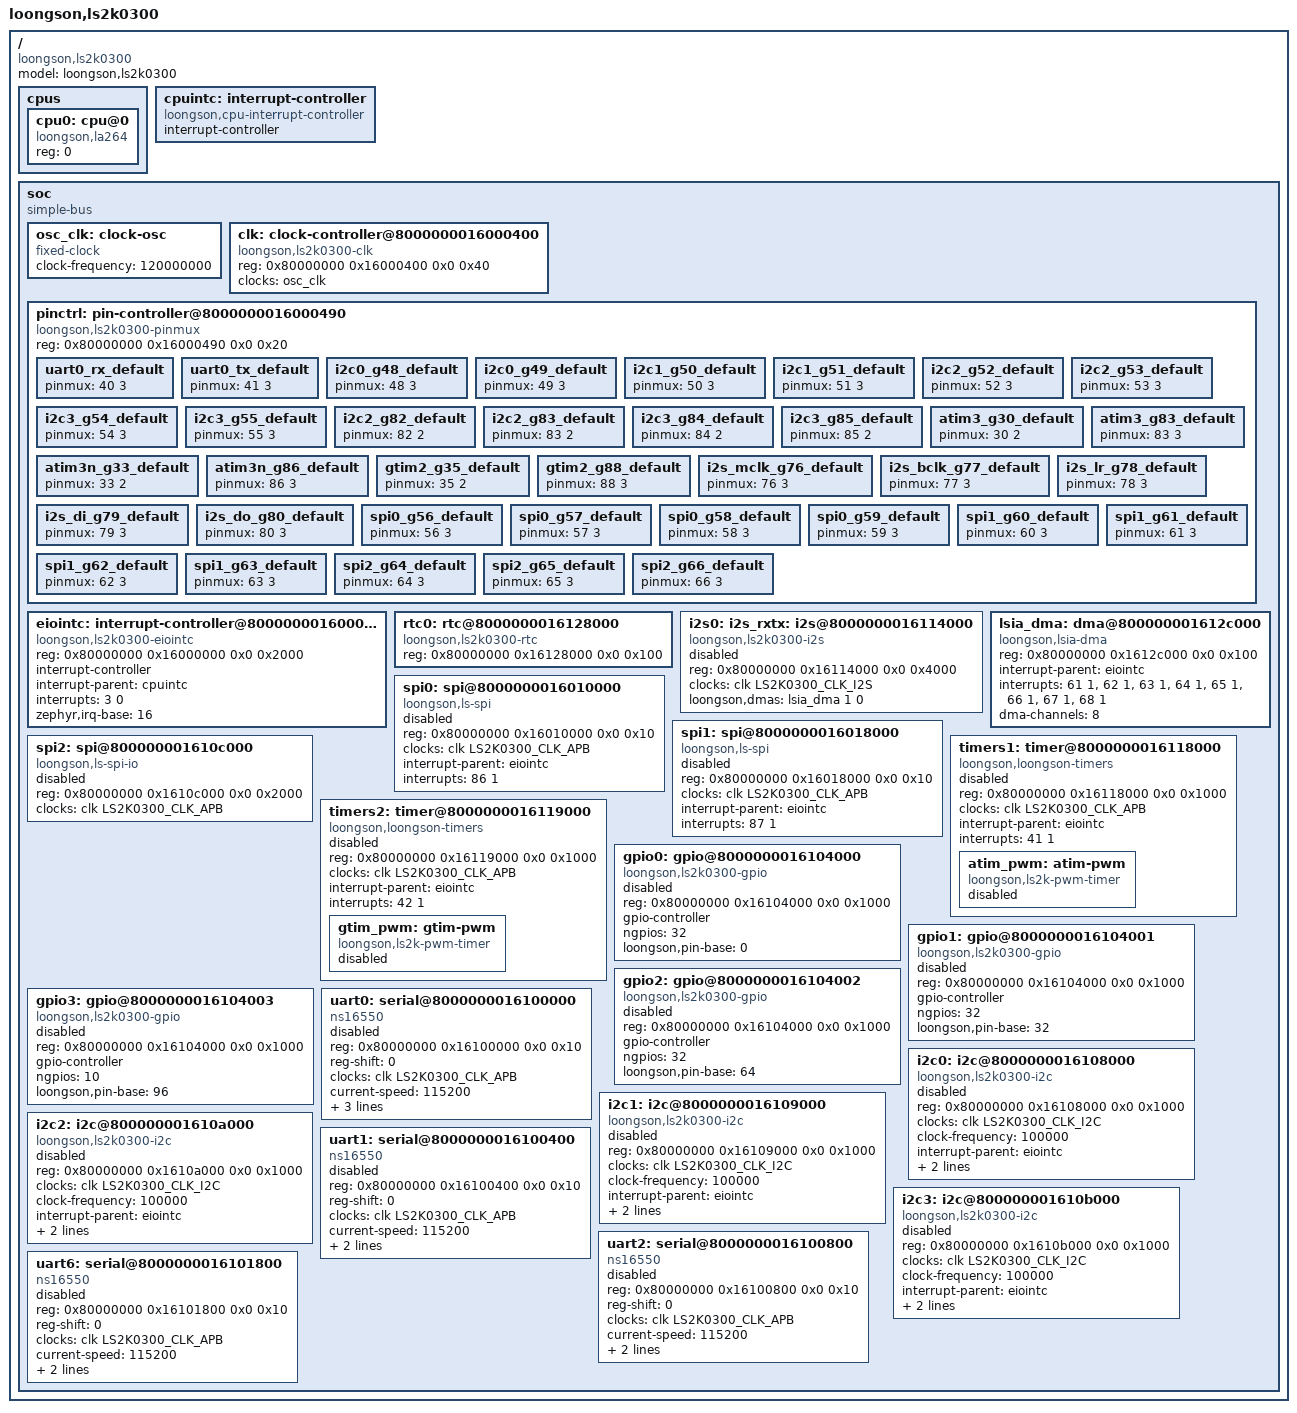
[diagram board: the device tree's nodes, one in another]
/*
 * SPDX-License-Identifier: Apache-2.0
 *
 * Loongson 2K0300 (LS2K0300, "ls2k300" family) - single LA264 core.
 *
 * Physical memory map:
 *
 *   0x9000_0000_0000_0000  DDR (size is board specific)
 *   0x1600_0000            SoC peripherals (LIO / APB)
 *   0x1640_0000            legacy ISA window
 *
 * Interrupts are numbered in a flat, SoC wide space:
 *
 *   0..15    CPU interrupt lines (ESTAT.IS[15:0], enabled through ECFG.LIE)
 *   16..143  EIOINTC vectors 0..127
 *
 * Peripheral nodes therefore carry the *flat* number in their "interrupts"
 * entry (e.g. <16 1> is vector 0 of the EIOINTC with priority 1).
 *
 * The EIOINTC is the interrupt controller of this port: the SoC wires every
 * peripheral interrupt to it, each source with a vector of its own. Its
 * predecessor, the legacy LIOINTC, is not modelled - it aggregates several
 * sources per line (uart2..uart5 share one, for example), which a static ISR
 * table can only serve one of - and its driver, binding and nodes were removed
 * once the EIOINTC took over. Its hardware facts are kept in the port notes
 * (`.vscode/skills/ls2k0300-port/references/hardware-registers.md`) for a
 * future 2K SoC that has no extended controller.
 */

/dts-v1/;

#include <zephyr/dt-bindings/clock/loongson,ls2k0300-clk.h>

/ {
	#address-cells = <2>;
	#size-cells = <2>;
	model = "loongson,ls2k0300";
	compatible = "loongson,ls2k0300";

	cpus {
		#address-cells = <1>;
		#size-cells = <0>;

		cpu0: cpu@0 {
			device_type = "cpu";
			compatible = "loongson,la264";
			reg = <0>;
		};
	};

	cpuintc: interrupt-controller {
		compatible = "loongson,cpu-interrupt-controller";
		interrupt-controller;
		#interrupt-cells = <2>;
	};

	soc {
		#address-cells = <2>;
		#size-cells = <2>;
		compatible = "simple-bus";
		ranges;

		/*
		 * The 120 MHz reference oscillator and the clock controller.
		 *
		 * The controller is driven read only: u-boot locks the PLLs before
		 * it hands over, so a consumer asks for the resulting rate instead
		 * of carrying a hard coded frequency in its node:
		 *
		 *     clocks = <&clk LS2K0300_CLK_APB>;
		 *
		 * That matters most for the console UART, whose baud rate divisor
		 * is CLKin / (16 * baud) and which therefore needs the real APB
		 * clock (200 MHz on this board), not a guess.
		 */
		osc_clk: clock-osc {
			compatible = "fixed-clock";
			#clock-cells = <0>;
			clock-frequency = <120000000>;
		};

		clk: clock-controller@8000000016000400 {
			compatible = "loongson,ls2k0300-clk";
			reg = <0x80000000 0x16000400 0x0 0x40>;
			clocks = <&osc_clk>;
			clock-names = "ref_clk";
			#clock-cells = <1>;
			status = "okay";
		};

		/*
		 * Pin mux: the GPIO_CFG registers at 0x1600_0490, two bits per
		 * GPIO (16 pins per register). A state lists (pin, function)
		 * pairs, see dts/bindings/pinctrl/loongson,ls2k0300-pinmux.yaml.
		 */
		pinctrl: pin-controller@8000000016000490 {
			compatible = "loongson,ls2k0300-pinmux";
			reg = <0x80000000 0x16000490 0x0 0x20>;
			status = "okay";

			/*
			 * Console pins: GPIO40 = uart0_rx, GPIO41 = uart0_tx,
			 * both on their primary function. This is the same setting
			 * the vendor device tree writes as
			 * "pinctrl-single,bits = <0x8 0x000f0000 0x000f0000>".
			 *
			 * Needed because u-boot only configures what it drives:
			 * measured on this board uart0_rx was still left in the
			 * GPIO setting, so the console transmitted but never
			 * received and the shell could not be typed into.
			 */
			uart0_rx_default: uart0_rx_default {
				pinmux = <40 3>;
			};

			uart0_tx_default: uart0_tx_default {
				pinmux = <41 3>;
			};

			/*
			 * I2C pins, all on their primary function, the same
			 * setting the vendor device tree writes for GPIO48..55
			 * in the pin mux word at offset 0xc (GPIO_CFG3):
			 *
			 *   i2c0_pins: pinctrl-single,bits = <0xc 0x0000000f 0x0000000f>;
			 *   i2c1_pins: pinctrl-single,bits = <0xc 0x000000f0 0x000000f0>;
			 *   i2c2_pins: pinctrl-single,bits = <0xc 0x00000f00 0x00000f00>;
			 *   i2c3_pins: pinctrl-single,bits = <0xc 0x0000f000 0x0000f000>;
			 */
			i2c0_g48_default: i2c0_g48_default {
				pinmux = <48 3>;
			};

			i2c0_g49_default: i2c0_g49_default {
				pinmux = <49 3>;
			};

			i2c1_g50_default: i2c1_g50_default {
				pinmux = <50 3>;
			};

			i2c1_g51_default: i2c1_g51_default {
				pinmux = <51 3>;
			};

			i2c2_g52_default: i2c2_g52_default {
				pinmux = <52 3>;
			};

			i2c2_g53_default: i2c2_g53_default {
				pinmux = <53 3>;
			};

			i2c3_g54_default: i2c3_g54_default {
				pinmux = <54 3>;
			};

			i2c3_g55_default: i2c3_g55_default {
				pinmux = <55 3>;
			};

			/*
			 * Mainline also defines an alternative pad group for i2c2
			 * and i2c3, on function 2 instead of 3:
			 *
			 *   i2c2_G82_G83_pins: pinctrl-single,bits = <0x14 0x000000a0 0x000000f0>;
			 *   i2c3_G84_G85_pins: pinctrl-single,bits = <0x14 0x00000a00 0x00000f00>;
			 *
			 * i.e. both fields 0b10 in the pin mux word at offset 0x14
			 * (GPIO80..95). A board picks one group per bus by
			 * referencing its two states in the controller's pinctrl-0;
			 * the controllers above default to the G52..G55 group.
			 */
			i2c2_g82_default: i2c2_g82_default {
				pinmux = <82 2>;
			};

			i2c2_g83_default: i2c2_g83_default {
				pinmux = <83 2>;
			};

			i2c3_g84_default: i2c3_g84_default {
				pinmux = <84 2>;
			};

			i2c3_g85_default: i2c3_g85_default {
				pinmux = <85 2>;
			};

			/*
			 * ATIM/GTIM channel pins, taken from the vendor device
			 * tree's pin mux table (each entry's
			 * "pinctrl-single,bits" decoded to the port's
			 * (pin, function) form). Channel 3 is the one Linux muxes
			 * for the LCD backlight on the 99pi board:
			 *
			 *   ATIM1 G28 f2 / G81 f3    ATIM1N G31 f2 / G84 f3
			 *   ATIM2 G29 f2 / G82 f3    ATIM2N G32 f2 / G85 f3
			 *   ATIM3 G30 f2 / G83 f3    ATIM3N G33 f2 / G86 f3
			 *   ATIM4 G76 f1 / G101 f1
			 *   GTIM1 G34 f2 / G87 f3    GTIM2 G35 f2 / G88 f3
			 *   GTIM3 G36 f2 / G89 f3    GTIM4 G77 f1 / G102 f1
			 *
			 * A board picks one pin per channel. Note that G82..G85
			 * also carry the alternative i2c2/i2c3 groups above, so a
			 * board that uses those buses must take its PWM channels
			 * elsewhere (G30 for channel 3, G28/G29 for 1/2, ...).
			 */
			atim3_g30_default: atim3_g30_default {
				pinmux = <30 2>;
			};

			atim3_g83_default: atim3_g83_default {
				pinmux = <83 3>;
			};

			/*
			 * The complementary outputs exist on the ATIM only
			 * (ATIM1N..ATIM3N, i.e. CH1N..CH3N); the driver enables
			 * them together with their channel, so referencing one of
			 * these states in the block's pinctrl-0 is all it takes
			 * to bring the pin out.
			 */
			atim3n_g33_default: atim3n_g33_default {
				pinmux = <33 2>;
			};

			atim3n_g86_default: atim3n_g86_default {
				pinmux = <86 3>;
			};

			/*
			 * GTIM channel 2 (the "TIM2_CH2" of the vendor tables):
			 * GPIO35 carries it on the m0 mux, GPIO88 on m1 - the pin
			 * Linux switches for the 99pi's second PWM group. Add the
			 * pins of the other channels from the table above the same
			 * way (three lines per pin).
			 */
			gtim2_g35_default: gtim2_g35_default {
				pinmux = <35 2>;
			};

			gtim2_g88_default: gtim2_g88_default {
				pinmux = <88 3>;
			};

			/*
			 * I2S pins, all on their I2S function. The mapping is the
			 * one of the manual's pin table and of the vendor device
			 * tree's "i2s_pins" group:
			 *
			 *   GPIO76 = i2s_mclk     GPIO79 = i2s_datai
			 *   GPIO77 = i2s_bclk     GPIO80 = i2s_datao
			 *   GPIO78 = i2s_lr
			 *
			 * GPIO76 also carries ATIM4 (function 1), GPIO77 GTIM4
			 * (function 1), so a board picks one of the two functions
			 * per pin by referencing the matching state.
			 */
			i2s_mclk_g76_default: i2s_mclk_g76_default {
				pinmux = <76 3>;
			};

			i2s_bclk_g77_default: i2s_bclk_g77_default {
				pinmux = <77 3>;
			};

			i2s_lr_g78_default: i2s_lr_g78_default {
				pinmux = <78 3>;
			};

			i2s_di_g79_default: i2s_di_g79_default {
				pinmux = <79 3>;
			};

			i2s_do_g80_default: i2s_do_g80_default {
				pinmux = <80 3>;
			};

			/*
			 * SPI0/SPI1 pins, all on their main function - the
			 * vendor device tree's "spi0_pins"/"spi1_pins" groups
			 * decoded to the port's (pin, function) form:
			 *
			 *   SPI0 G56 GCLK / G57 MISO / G58 MOSI / G59 CS
			 *   SPI1 G60 GCLK / G61 MISO / G62 MOSI / G63 CS
			 */
			spi0_g56_default: spi0_g56_default {
				pinmux = <56 3>;
			};

			spi0_g57_default: spi0_g57_default {
				pinmux = <57 3>;
			};

			spi0_g58_default: spi0_g58_default {
				pinmux = <58 3>;
			};

			spi0_g59_default: spi0_g59_default {
				pinmux = <59 3>;
			};

			spi1_g60_default: spi1_g60_default {
				pinmux = <60 3>;
			};

			spi1_g61_default: spi1_g61_default {
				pinmux = <61 3>;
			};

			spi1_g62_default: spi1_g62_default {
				pinmux = <62 3>;
			};

			spi1_g63_default: spi1_g63_default {
				pinmux = <63 3>;
			};

			/*
			 * SPI2 pins on their main function - the vendor device
			 * tree's "spi2_pins" group decoded (G64 = clock,
			 * G65 = miso, G66 = mosi). GPIO67, the fourth pin of
			 * the group, stays a GPIO: the ls-spi-io block has no
			 * chip select register, so its CS line is driven as a
			 * plain GPIO (the controller's "cs-gpios").
			 */
			spi2_g64_default: spi2_g64_default {
				pinmux = <64 3>;
			};

			spi2_g65_default: spi2_g65_default {
				pinmux = <65 3>;
			};

			spi2_g66_default: spi2_g66_default {
				pinmux = <66 3>;
			};
		};

		/*
		 * EIOINTC ("EXTIOI"): 128 extended interrupt vectors, each one
		 * separately maskable and routable, all of them cascaded onto CPU
		 * line 3 (INT1 - the vendor device tree cascades it there as
		 * well). The vector assignment is table 3-48 of the 2K0300 user
		 * manual:
		 *
		 *   0..9     UART0..UART9       70, 71    SPI0, SPI1
		 *   10..13   I2C0..I2C3         75, 76    GMAC0, GMAC1
		 *   14, 15   SPI2, SPI3         78        THSENS
		 *   16..23   CAN0..CAN3 core and buffer each
		 *   25..27   ATIMER, GTIMER, BTIMER
		 *   28..31   PWM0..PWM3
		 *   45..52   APB-DMA0..APB-DMA7
		 *   62..64   RTC-INT0..RTC-INT2
		 *   79..105  GPIO0..GPIO105, four pins per vector
		 *
		 * "reg" is the SoC system register window: the controller's
		 * register file sits at offset 0x1600 (enable), 0x1640
		 * (polarity), 0x1700 (device status), 0x1800 (per core status and
		 * clear) and 0x14c0 (vector routing), and the master enable is bit
		 * 19 of the chip configuration register at offset 0x100.
		 */
		eiointc: interrupt-controller@8000000016000000 {
			compatible = "loongson,ls2k0300-eiointc";
			reg = <0x80000000 0x16000000 0x0 0x2000>;
			interrupt-controller;
			#interrupt-cells = <2>;
			interrupt-parent = <&cpuintc>;
			interrupts = <3 0>;
			zephyr,irq-base = <16>;
		};

		/*
		 * RTC: battery backed wall clock. The block's TOY counter counts
		 * year/month/day/hour/minute/second (plus tenths) off the
		 * 32.768 kHz crystal and is the time the driver reads and
		 * writes; the register map is chapter 25 of the user manual.
		 *
		 * Its TOY match alarm does not work on this SoC (mainline Linux
		 * carries the variant under LOONGSON_RTC_ALARM_WORKAROUND), so
		 * the node carries no interrupt even though the interrupt tables
		 * list RTC-INT0..2 / RTC-TICK / TOY-TICK.
		 *
		 * Always present and needing no pins, so it is enabled here
		 * rather than per board.
		 */
		rtc0: rtc@8000000016128000 {
			compatible = "loongson,ls2k0300-rtc";
			reg = <0x80000000 0x16128000 0x0 0x100>;
			status = "okay";
		};

		/*
		 * I2S controller ("IIS", user manual chapter 11): one stereo
		 * interface with an 8 byte FIFO per direction, an integer bit
		 * clock divider and a fractional divider for the codec system
		 * clock (MCLK) that the bit clock is derived from.
		 *
		 * Its interrupt is EIOINTC vector 24 (flat IRQ 40); the block's
		 * interrupt sources stay unused - they report FIFO
		 * overflow/underflow, which cannot pace a stream - so the node
		 * carries no interrupt property. The data path is paced by the
		 * DMA controller below instead.
		 *
		 * Kept disabled here: the five interface pins (GPIO76 MCLK,
		 * GPIO77 BCLK, GPIO78 LR, GPIO79 data in, GPIO80 data out) are
		 * board wiring, and so is the question whether anything drives
		 * the codec system clock.
		 */
		/* The second label is what samples/drivers/i2s/echo looks for */
		i2s0: i2s_rxtx: i2s@8000000016114000 {
			compatible = "loongson,ls2k0300-i2s";
			reg = <0x80000000 0x16114000 0x0 0x4000>;
			#address-cells = <1>;
			#size-cells = <0>;
			/*
			 * The clock both dividers count against (the bit clock
			 * ratio in IISConfig0, the system clock ratio in
			 * IISConfig1). The manual calls it the "bus clock" and
			 * the vendor device tree carries clock-frequency =
			 * <100000000> for this node; on this board the clock
			 * controller reports exactly that - 100 MHz - for
			 * LS2K0300_CLK_I2S (the NODE PLL branch of the
			 * controller), while LS2K0300_CLK_APB, the bus clock of
			 * the UART/I2C/... peripherals, is 200 MHz. The vendor's
			 * own config1 math divides that 100 MHz down to its
			 * 128 fs system clock, which is the same number, so this
			 * property points at the I2S clock.
			 *
			 * If a board turns out to divide another clock, pointing
			 * this property at it is the single change needed - the
			 * driver just reads "clocks".
			 */
			clocks = <&clk LS2K0300_CLK_I2S>;
			/*
			 * The DMA controller moves the data: its transmit request
			 * is wired to channel 1 and its receive request to channel
			 * 0, which is the mapping the vendor device tree uses
			 * ("dmas = <&dma 0 0xaf>, <&dma 1 0xbf>"). There is no
			 * request select register, so these two numbers are all
			 * there is to get right.
			 */
			loongson,dmas = <&lsia_dma 1 0>;
			status = "disabled";
		};

		/*
		 * LSIA DMA controller, "dma@1612c000" in the vendor tree
		 * (compatible "loongson,lsia-dma"): eight channels, four
		 * registers each 0x14 apart - CCR at 0x08, CNDTR at 0x0c, CPAR at
		 * 0x10, CMAR at 0x14 - plus two status registers at 0x00/0x04
		 * holding a four bit nibble per channel (transfer complete in
		 * bit 1, half transfer in bit 2). The vendor kernel drives it
		 * through drivers/dma/lsia_dma.c, this port through
		 * drivers/dma/dma_loongson_lsia.c.
		 *
		 * The data requests are wired to fixed channels - the I2S
		 * transmit on channel 1 and its receive on channel 0 - and the
		 * controller has no request select register, so a consumer
		 * names its channel and nothing else (the "loongson,dmas"
		 * property of the I2S node carries both of its channels for
		 * that driver).
		 */
		lsia_dma: dma@800000001612c000 {
			compatible = "loongson,lsia-dma";
			reg = <0x80000000 0x1612c000 0x0 0x100>;
			/*
			 * One interrupt line per channel: APB-DMA0..7 on vectors
			 * 45..52 of table 3-48 - 61..68 in the flat, SoC wide
			 * numbering this port carries in "interrupts". Confirmed
			 * on hardware: with the channels running, the EIOINTC's
			 * raw, enable-independent status latches exactly vector
			 * 46 (channel 1) while channel 0's expected bit stays
			 * clear. (The vendor tree lists the same lines as
			 * liointc0 inputs 23..30 - those legacy numbers are not
			 * this controller's vectors; a translation read off
			 * liointc input arithmetic put the channels on 23..30
			 * once and the board silently disagreed.)
			 */
			interrupt-parent = <&eiointc>;
			interrupts = <61 1>, <62 1>, <63 1>, <64 1>,
				     <65 1>, <66 1>, <67 1>, <68 1>;
			dma-channels = <8>;
			#dma-cells = <2>;
			/* The namespaced form, for the "loongson,dmas" property */
			#loongson,dma-cells = <2>;
			status = "okay";
		};

		/*
		 * SPI0/SPI1, "spi@0x16010000"/"spi@0x16018000" of the vendor
		 * device tree (compatible "loongson,ls-spi", user manual
		 * chapter 9): a simple polled SPI master with a one byte FIFO
		 * port, four hardware chip selects and the APB/DEVS clock
		 * (200 MHz on this board) as its divider input, so SCLK runs
		 * from 100 MHz down to about 49 kHz.
		 *
		 * The same block also drives a memory-mapped flash window
		 * (SPI0 boot at 0x1c000000, MEM at 0x10000000) that u-boot uses
		 * for XIP; the driver leaves SFC_PARAM.memory_en cleared and
		 * drives the bus purely through the IO registers. The two
		 * "loongson,ls-spi-io" blocks (SPI2 @0x1610c000, SPI3
		 * @0x1610e000) are a different register file (CR1..CR3, CFG1..3)
		 * and are not modelled here.
		 */
		spi0: spi@8000000016010000 {
			compatible = "loongson,ls-spi";
			reg = <0x80000000 0x16010000 0x0 0x10>;
			clocks = <&clk LS2K0300_CLK_APB>;
			clock-names = "apb";
			#address-cells = <1>;
			#size-cells = <0>;
			interrupt-parent = <&eiointc>;
			interrupts = <86 1>; /* vector 70, table 3-48 */
			status = "disabled";
		};

		spi1: spi@8000000016018000 {
			compatible = "loongson,ls-spi";
			reg = <0x80000000 0x16018000 0x0 0x10>;
			clocks = <&clk LS2K0300_CLK_APB>;
			clock-names = "apb";
			#address-cells = <1>;
			#size-cells = <0>;
			interrupt-parent = <&eiointc>;
			interrupts = <87 1>; /* vector 71, table 3-48 */
			status = "disabled";
		};

		/*
		 * SPI2, "spi@0x1610c000" of the vendor device tree
		 * (compatible "loongson,ls-spi-io"): the second register file
		 * (user manual chapter 10) - 32 bit registers, one byte per
		 * CSTART transfer, and no hardware chip selects (a board
		 * drives its CS lines as plain GPIOs through "cs-gpios").
		 * SPI3 (0x1610e000) is the same design and is left out until a
		 * board needs it.
		 */
		spi2: spi@800000001610c000 {
			compatible = "loongson,ls-spi-io";
			reg = <0x80000000 0x1610c000 0x0 0x2000>;
			clocks = <&clk LS2K0300_CLK_APB>;
			clock-names = "apb";
			#address-cells = <1>;
			#size-cells = <0>;
			status = "disabled";
		};

		/*
		 * SoC timer blocks, ported from the vendor Linux device tree
		 * (arch/loongarch/boot/dts/loongson-2k0300.dtsi, "timers1" and
		 * "timers2"): STM32 style general purpose timers on the APB bus
		 * (user manual chapters 18/19), four channels each, input capture
		 * and output compare/PWM. Interrupt mapping and the (unused)
		 * BTIM block are described in the binding.
		 *
		 * Both blocks stay disabled like in Linux - the channel pins are
		 * board wiring - and each one carries the PWM child that Linux
		 * hangs off it, which is what the PWM driver binds to
		 * (drivers/pwm/pwm_loongson_ls_timer.c). The two blocks are
		 * independent, so a board that enables both gets two PWM
		 * frequencies at the same time.
		 *
		 * Linux names both children "pwm"; here they are called
		 * "atim-pwm" and "gtim-pwm" instead, because a Zephyr device is
		 * addressed by its node name and two devices with the same name
		 * would be indistinguishable (the node labels atim_pwm/gtim_pwm
		 * work as well).
		 *
		 * Left out of the Linux node: "dmas"/"dma-names", which this port
		 * has no DMA controller node for - only the capture path needs
		 * them, and capture is not implemented.
		 */
		timers1: timer@8000000016118000 {
			compatible = "loongson,loongson-timers";
			reg = <0x80000000 0x16118000 0x0 0x1000>;
			clocks = <&clk LS2K0300_CLK_APB>;
			clock-names = "int";
			interrupt-parent = <&eiointc>;
			interrupts = <41 1>;
			status = "disabled";

			atim_pwm: atim-pwm {
				compatible = "loongson,ls2k-pwm-timer";
				#pwm-cells = <3>;
				status = "disabled";
			};
		};

		timers2: timer@8000000016119000 {
			compatible = "loongson,loongson-timers";
			reg = <0x80000000 0x16119000 0x0 0x1000>;
			clocks = <&clk LS2K0300_CLK_APB>;
			clock-names = "int";

			interrupt-parent = <&eiointc>;
			interrupts = <42 1>;
			status = "disabled";

			gtim_pwm: gtim-pwm {
				compatible = "loongson,ls2k-pwm-timer";
				#pwm-cells = <3>;
				status = "disabled";
			};
		};

		/*
		 * GPIO controller: 106 byte-controlled pins, split into banks
		 * of at most 32 pins so that Zephyr pin numbers stay within
		 * the 32 bit port mask of the GPIO API. The interrupt part of
		 * the block is not modelled yet.
		 *
		 * Bank N covers IP pins (N * 32) .. (N * 32 + ngpios - 1),
		 * e.g. the backlight/user LED line GPIO43 is <&gpio1 11>.
		 *
		 * All banks share the one 4 KiB register block, so they carry the
		 * same reg value and the unit addresses in the node names exist
		 * only to keep the names unique. dtc flags that as a
		 * simple_bus_reg warning; the alternative would be to encode an
		 * address per bank that the hardware does not have.
		 */
		gpio0: gpio@8000000016104000 {
			compatible = "loongson,ls2k0300-gpio";
			reg = <0x80000000 0x16104000 0x0 0x1000>;
			gpio-controller;
			#gpio-cells = <2>;
			ngpios = <32>;
			loongson,pin-base = <0>;
			status = "disabled";
		};

		gpio1: gpio@8000000016104001 {
			compatible = "loongson,ls2k0300-gpio";
			reg = <0x80000000 0x16104000 0x0 0x1000>;
			gpio-controller;
			#gpio-cells = <2>;
			ngpios = <32>;
			loongson,pin-base = <32>;
			status = "disabled";
		};

		gpio2: gpio@8000000016104002 {
			compatible = "loongson,ls2k0300-gpio";
			reg = <0x80000000 0x16104000 0x0 0x1000>;
			gpio-controller;
			#gpio-cells = <2>;
			ngpios = <32>;
			loongson,pin-base = <64>;
			status = "disabled";
		};

		gpio3: gpio@8000000016104003 {
			compatible = "loongson,ls2k0300-gpio";
			reg = <0x80000000 0x16104000 0x0 0x1000>;
			gpio-controller;
			#gpio-cells = <2>;
			ngpios = <10>;
			loongson,pin-base = <96>;
			status = "disabled";
		};

		/*
		 * MMIO is reached through the uncached direct map window
		 * (0x8000_0000_0000_0000 | physical address), which reset.S
		 * programs as DMW0. The plain physical address 0x1610_0000 is
		 * not inside any direct map window, so using it would need a TLB
		 * entry the kernel does not own and would fault.
		 */
		uart0: serial@8000000016100000 {
			compatible = "ns16550";
			reg = <0x80000000 0x16100000 0x0 0x10>;
			reg-shift = <0>;
			clocks = <&clk LS2K0300_CLK_APB>;
			current-speed = <115200>;
			interrupt-parent = <&eiointc>;
			interrupts = <16 1>;
			pinctrl-0 = <&uart0_rx_default &uart0_tx_default>;
			pinctrl-names = "default";
			status = "disabled";
		};

		/*
		 * I2C controllers ("loongson,ls2k0300-i2c"): the SoC's "fast
		 * I2C" peripheral, 32 bit registers (CR1/CR2/DR/SR1/SR2/CCR/
		 * TRISE) with the start/stop/ack generation in CR1 and level
		 * status flags in SR1/SR2. The driver polls those flags, so no
		 * interrupt line is needed. Addresses, pad groups and interrupt
		 * lines follow mainline Linux,
		 * arch/loongarch/boot/dts/loongson-2k0300.dtsi:
		 *
		 *   i2c0 @ 0x16108000, EIOINTC vector 10, G48/G49
		 *   i2c1 @ 0x16109000, EIOINTC vector 11, G50/G51
		 *   i2c2 @ 0x1610a000, EIOINTC vector 12, G52/G53 (or G82/G83)
		 *   i2c3 @ 0x1610b000, EIOINTC vector 13, G54/G55 (or G84/G85)
		 *
		 * The vectors become the flat IRQs 26/27/28/29. The driver
		 * polls the controller's completion flag and needs no interrupt
		 * line at all - the property is kept so the node stays faithful
		 * to mainline and for a future interrupt driven implementation.
		 *
		 * Mainline carries the *input* clock in "clock-frequency" (200
		 * MHz, the APB bus clock). Here that comes from the clock
		 * controller instead, and "clock-frequency" carries the I2C bus
		 * speed as in every other Zephyr I2C binding.
		 */
		i2c0: i2c@8000000016108000 {
			compatible = "loongson,ls2k0300-i2c";
			reg = <0x80000000 0x16108000 0x0 0x1000>;
			#address-cells = <1>;
			#size-cells = <0>;
			clocks = <&clk LS2K0300_CLK_I2C>;
			clock-frequency = <100000>;
			interrupt-parent = <&eiointc>;
			interrupts = <26 1>;
			pinctrl-0 = <&i2c0_g48_default &i2c0_g49_default>;
			pinctrl-names = "default";
			status = "disabled";
		};

		i2c1: i2c@8000000016109000 {
			compatible = "loongson,ls2k0300-i2c";
			reg = <0x80000000 0x16109000 0x0 0x1000>;
			#address-cells = <1>;
			#size-cells = <0>;
			clocks = <&clk LS2K0300_CLK_I2C>;
			clock-frequency = <100000>;
			interrupt-parent = <&eiointc>;
			interrupts = <27 1>;
			pinctrl-0 = <&i2c1_g50_default &i2c1_g51_default>;
			pinctrl-names = "default";
			status = "disabled";
		};

		i2c2: i2c@800000001610a000 {
			compatible = "loongson,ls2k0300-i2c";
			reg = <0x80000000 0x1610a000 0x0 0x1000>;
			#address-cells = <1>;
			#size-cells = <0>;
			clocks = <&clk LS2K0300_CLK_I2C>;
			clock-frequency = <100000>;
			interrupt-parent = <&eiointc>;
			interrupts = <28 1>;
			pinctrl-0 = <&i2c2_g52_default &i2c2_g53_default>;
			pinctrl-names = "default";
			status = "disabled";
		};

		i2c3: i2c@800000001610b000 {
			compatible = "loongson,ls2k0300-i2c";
			reg = <0x80000000 0x1610b000 0x0 0x1000>;
			#address-cells = <1>;
			#size-cells = <0>;
			clocks = <&clk LS2K0300_CLK_I2C>;
			clock-frequency = <100000>;
			interrupt-parent = <&eiointc>;
			interrupts = <29 1>;
			pinctrl-0 = <&i2c3_g54_default &i2c3_g55_default>;
			pinctrl-names = "default";
			status = "disabled";
		};

		uart1: serial@8000000016100400 {
			compatible = "ns16550";
			reg = <0x80000000 0x16100400 0x0 0x10>;
			reg-shift = <0>;
			clocks = <&clk LS2K0300_CLK_APB>;
			current-speed = <115200>;
			interrupt-parent = <&eiointc>;
			interrupts = <17 1>;
			status = "disabled";
		};

		uart2: serial@8000000016100800 {
			compatible = "ns16550";
			reg = <0x80000000 0x16100800 0x0 0x10>;
			reg-shift = <0>;
			clocks = <&clk LS2K0300_CLK_APB>;
			current-speed = <115200>;
			interrupt-parent = <&eiointc>;
			interrupts = <18 1>;
			status = "disabled";
		};

		/*
		 * uart3..uart5 and uart7..uart9 are not described yet: every one
		 * of them has a vector of its own on the EIOINTC (uart3 = vector
		 * 3 / flat IRQ 19 up to uart9 = vector 9 / flat IRQ 25), so they
		 * can be added here whenever a board needs them.
		 */
		uart6: serial@8000000016101800 {
			compatible = "ns16550";
			reg = <0x80000000 0x16101800 0x0 0x10>;
			reg-shift = <0>;
			clocks = <&clk LS2K0300_CLK_APB>;
			current-speed = <115200>;
			interrupt-parent = <&eiointc>;
			interrupts = <22 1>;
			status = "disabled";
		};
	};
};
